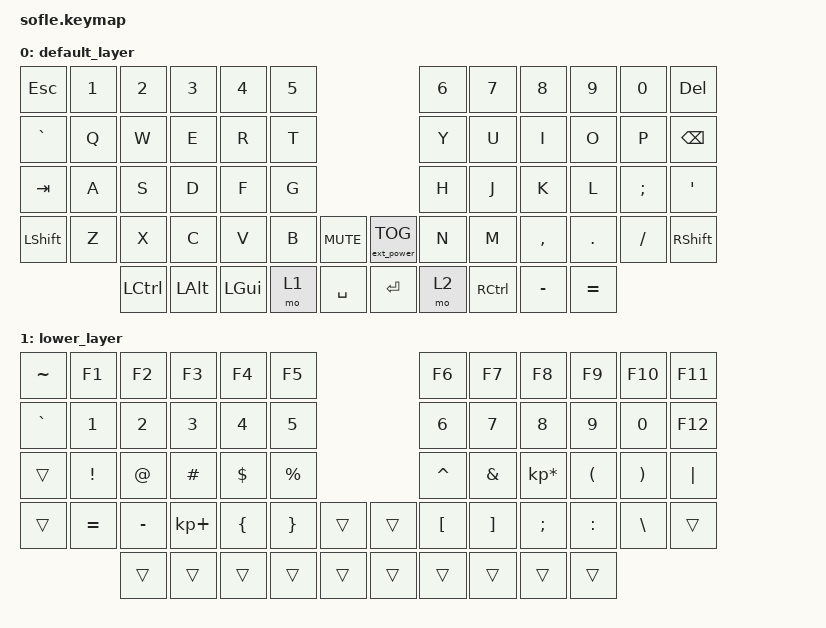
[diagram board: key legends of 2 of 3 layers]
/*
 * Copyright (c) 2020 The ZMK Contributors
 *
 * SPDX-License-Identifier: MIT
 */

#define ZMK_POINTING_DEFAULT_SCRL_VAL 140

#include <behaviors.dtsi>

#include <dt-bindings/zmk/pointing.h>
#include <dt-bindings/zmk/keys.h>
#include <dt-bindings/zmk/bt.h>
#include <dt-bindings/zmk/ext_power.h>
#include <dt-bindings/zmk/rgb.h>
#include <dt-bindings/led/led.h>

&nice_view_spi {
    cs-gpios = <&gpio1 1 GPIO_ACTIVE_HIGH>;
};

&pinctrl {
    spi3_default: spi3_default {
        group1 {
            psels = <NRF_PSEL(SPIM_MOSI, 0, 6)>;
        };
    };

    spi3_sleep: spi3_sleep {
        group1 {
            psels = <NRF_PSEL(SPIM_MOSI, 0, 6)>;
            low-power-enable;
        };
    };
};

&spi3 {
    compatible = "nordic,nrf-spim";
    status = "okay";

    pinctrl-0 = <&spi3_default>;
    pinctrl-1 = <&spi3_sleep>;
    pinctrl-names = "default", "sleep";

    led_strip: ws2812@0 {
        compatible = "worldsemi,ws2812-spi";

        /* SPI */
        reg = <0>; /* ignored, but necessary for SPI bindings */
        spi-max-frequency = <4000000>;

        /* WS2812 */
        chain-length = <29>; /* arbitrary; change at will */
        spi-one-frame = <0x70>;
        spi-zero-frame = <0x40>;

        color-mapping = <
            LED_COLOR_ID_GREEN
            LED_COLOR_ID_RED
            LED_COLOR_ID_BLUE
        >;
    };
};

/ {
    chosen {
        zmk,underglow = &led_strip;
    };
};

/ {
    behaviors {
        ud_encoder: ud_encoder {
            compatible = "zmk,behavior-sensor-rotate";
            #sensor-binding-cells = <0>;
            bindings = <&msc SCRL_DOWN>, <&msc SCRL_UP>;
            tap-ms = <30>;
        };
    };

    behaviors {
        lr_encoder: lr_encoder {
            compatible = "zmk,behavior-sensor-rotate";
            #sensor-binding-cells = <0>;
            bindings = <&msc SCRL_RIGHT>, <&msc SCRL_LEFT>;
            tap-ms = <30>;
        };
    };

    keymap {
        compatible = "zmk,keymap";

        default_layer {
// ------------------------------------------------------------------------------------------------------------------
// |  ESC  |  1  |  2  |  3   |  4   |  5   |                         |  6   |  7    |  8    |   9   |   0   |  Del  |
// |  `    |  Q  |  W  |  E   |  R   |  T   |                         |  Y   |  U    |  I    |   O   |   P   | BKSPC |
// |  TAB  |  A  |  S  |  D   |  F   |  G   |                         |  H   |  J    |  K    |   L   |   ;   |   '   |
// | SHIFT |  Z  |  X  |  C   |  V   |  B   |  MUTE  |        | ExtPw |  N   |  M    |  ,    |   .   |   /   | SHIFT |
//               | CTRL| ALT  | GUI  | LOWER|  SPACE |        | ENTER | RAISE| CTRL  | MINUS | EQUAL |
            bindings = <
&kp ESC   &kp N1 &kp N2   &kp N3   &kp N4    &kp N5                              &kp N6 &kp N7    &kp N8    &kp N9   &kp N0   &kp DEL
&kp GRAVE &kp Q  &kp W    &kp E    &kp R     &kp T                               &kp Y  &kp U     &kp I     &kp O    &kp P    &kp BSPC
&kp TAB   &kp A  &kp S    &kp D    &kp F     &kp G                               &kp H  &kp J     &kp K     &kp L    &kp SEMI &kp SQT
&kp LSHFT &kp Z  &kp X    &kp C    &kp V     &kp B  &kp C_MUTE &ext_power EP_TOG &kp N  &kp M     &kp COMMA &kp DOT  &kp FSLH &kp RSHFT
                 &kp LCTRL &kp LALT &kp LGUI &mo 1  &kp SPACE    &kp RET         &mo 2  &kp RCTRL &kp MINUS  &kp EQUAL
            >;

            sensor-bindings =
                <&lr_encoder>,
                <&ud_encoder>;
        };

        lower_layer {
// TODO: Some binds are waiting for shifted keycode support.
// ------------------------------------------------------------------------------------------------------------
// | ~     |  F1 |  F2 |  F3  |  F4  |  F5  |                   |  F6  |  F7   |  F8   |  F9  |  F10  |  F11  |
// | `     |   1 |   2 |   3  |   4  |   5  |                   |   6  |   7   |   8   |   9  |    0  |  F12  |
// |       |  !  |  @  |  #   |  $   |  %   |                   |  ^   |  &    |  *    |  (   |   )   |   |   |
// |       |  =  |  -  |  +   |  {   |  }   |        |  |       |  [   |  ]    |  ;    |  :   |   \   |       |
//               |     |      |      |      |        |  |       |      |       |       |      |
            bindings = <
&kp TILDE &kp F1    &kp F2    &kp F3      &kp F4    &kp F5                    &kp F6    &kp F7   &kp F8          &kp F9    &kp F10   &kp F11
&kp GRAVE &kp N1    &kp N2    &kp N3      &kp N4    &kp N5                    &kp N6    &kp N7   &kp N8          &kp N9    &kp N0    &kp F12
&trans    &kp EXCL  &kp AT    &kp HASH    &kp DLLR  &kp PRCNT                 &kp CARET &kp AMPS &kp KP_MULTIPLY &kp LPAR  &kp RPAR  &kp PIPE
&trans    &kp EQUAL &kp MINUS &kp KP_PLUS &kp LBRC  &kp RBRC  &trans   &trans &kp LBKT  &kp RBKT &kp SEMI        &kp COLON &kp BSLH  &trans
                    &trans    &trans      &trans    &trans    &trans   &trans &trans    &trans   &trans          &trans
            >;

            sensor-bindings =
                <&inc_dec_kp PG_UP PG_DN>,
                <&inc_dec_kp C_VOL_DN C_VOL_UP>;
        };

        raise_layer {
// ------------------------------------------------------------------------------------------------------------
// |BTCLR| BT1  | BT2  |  BT3  |  BT4  |  BT5 |                 |      |      |       |      |       |       |
// |     | INS  | PSCR | GUI   |       |      |                 | PGUP |      |   ^   |      |       |       |
// | ugBi| ALT  | CTRL | SHIFT |       | CAPS |                 | PGDN |   <- |   v   |  ->  |  DEL  | BKSPC |
// | ugBd| UNDO | CUT  | COPY  | PASTE |      |      |   | RGB  | ugEF | ugHi | ugSAi | ugBi |       |       |
//              |      |       |       |      |      |   |      |      | ugHd | ugSAd | ugBd |
            bindings = <
&bt BT_CLR       &bt BT_SEL 0  &bt BT_SEL 1  &bt BT_SEL 2  &bt BT_SEL 3  &bt BT_SEL 4                             &trans           &trans           &trans           &trans           &trans   &trans
&trans           &kp INS       &kp PSCRN     &kp K_CMENU   &trans        &trans                                   &kp PG_UP        &trans           &kp UP           &trans           &kp N0   &trans
&trans RGB_BRI  &kp LALT      &kp LCTRL     &kp LSHFT     &trans        &kp CLCK                                 &kp PG_DN        &kp LEFT         &kp DOWN         &kp RIGHT        &kp DEL  &kp BSPC
&trans RGB_BRD  &kp K_UNDO    &kp K_CUT     &kp K_COPY    &kp K_PASTE   &trans        &trans    &rgb_ug RGB_TOG  &rgb_ug RGB_EFF  &rgb_ug RGB_HUI  &rgb_ug RGB_SAI  &rgb_ug RGB_BRI  &trans   &trans
                               &trans        &trans        &trans        &trans        &trans    &trans           &trans           &rgb_ug RGB_HUD  &rgb_ug RGB_SAD  &rgb_ug RGB_BRD
            >;

            sensor-bindings =
                <&inc_dec_kp C_BRIGHTNESS_DEC C_BRIGHTNESS_INC>,
                <&inc_dec_kp PG_UP PG_DN>;
        };
    };
};
